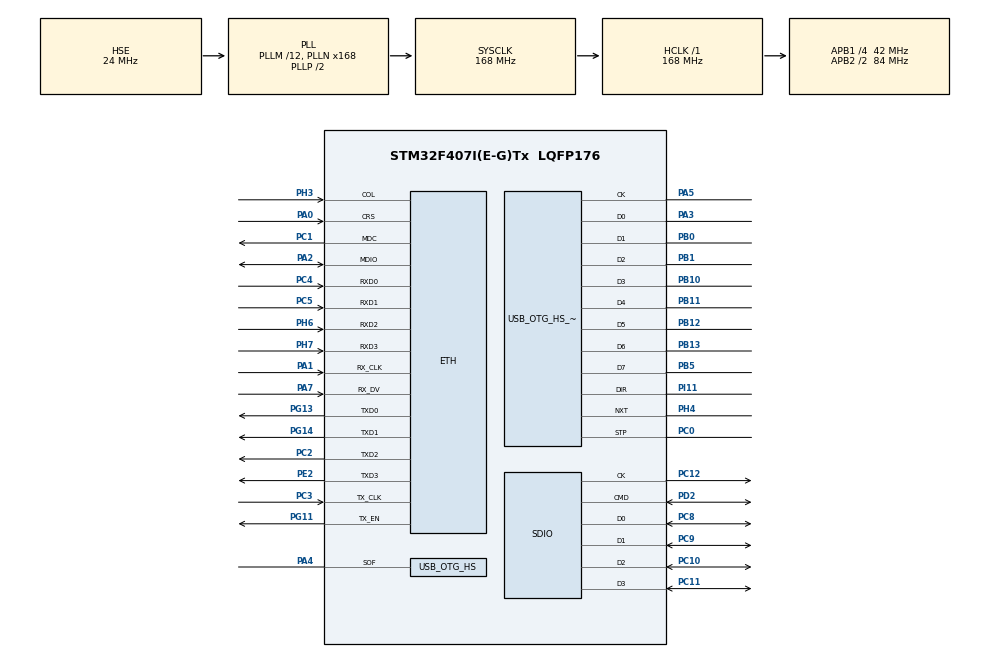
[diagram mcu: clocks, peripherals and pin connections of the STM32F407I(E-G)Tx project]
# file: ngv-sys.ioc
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LWIP.Version=v1.5.0_RC0_20160211_Cube
Mcu.Family=STM32F4
Mcu.Name=STM32F407I(E-G)Tx
Mcu.Package=LQFP176
NVIC.OTG_HS_IRQn=true\:0\:0\:false\:false\:true
NVIC.PriorityGroup=NVIC_PRIORITYGROUP_4
PA0-WKUP.Mode=MII
PA0-WKUP.Signal=ETH_CRS
PA1.Mode=MII
PA1.Signal=ETH_RX_CLK
PA2.Mode=MII
PA2.Signal=ETH_MDIO
PA3.Mode=Device_HS
PA3.Signal=USB_OTG_HS_ULPI_D0
PA4.Mode=Activate_SOF_FS
PA4.Signal=USB_OTG_HS_SOF
PA5.Mode=Device_HS
PA5.Signal=USB_OTG_HS_ULPI_CK
PA7.Mode=MII
PA7.Signal=ETH_RX_DV
PB0.Mode=Device_HS
PB0.Signal=USB_OTG_HS_ULPI_D1
PB1.Mode=Device_HS
PB1.Signal=USB_OTG_HS_ULPI_D2
PB10.Mode=Device_HS
PB10.Signal=USB_OTG_HS_ULPI_D3
PB11.Mode=Device_HS
PB11.Signal=USB_OTG_HS_ULPI_D4
PB12.Mode=Device_HS
PB12.Signal=USB_OTG_HS_ULPI_D5
PB13.Mode=Device_HS
PB13.Signal=USB_OTG_HS_ULPI_D6
PB5.Mode=Device_HS
PB5.Signal=USB_OTG_HS_ULPI_D7
PC0.Mode=Device_HS
PC0.Signal=USB_OTG_HS_ULPI_STP
PC1.Mode=MII
PC1.Signal=ETH_MDC
PC10.Mode=SD_4_bits_Wide_bus
PC10.Signal=SDIO_D2
PC11.Mode=SD_4_bits_Wide_bus
PC11.Signal=SDIO_D3
PC12.Mode=SD_4_bits_Wide_bus
PC12.Signal=SDIO_CK
PC14-OSC32_IN.Mode=LSE-External-Oscillator
PC14-OSC32_IN.Signal=RCC_OSC32_IN
PC15-OSC32_OUT.Mode=LSE-External-Oscillator
PC15-OSC32_OUT.Signal=RCC_OSC32_OUT
PC2.Mode=MII
PC2.Signal=ETH_TXD2
PC3.Mode=MII
PC3.Signal=ETH_TX_CLK
PC4.Mode=MII
PC4.Signal=ETH_RXD0
PC5.Mode=MII
PC5.Signal=ETH_RXD1
PC8.Mode=SD_4_bits_Wide_bus
PC8.Signal=SDIO_D0
PC9.Mode=SD_4_bits_Wide_bus
PC9.Signal=SDIO_D1
PD2.Mode=SD_4_bits_Wide_bus
PD2.Signal=SDIO_CMD
PE2.Mode=MII
PE2.Signal=ETH_TXD3
PG11.Mode=MII
PG11.Signal=ETH_TX_EN
PG13.Mode=MII
PG13.Signal=ETH_TXD0
PG14.Mode=MII
PG14.Signal=ETH_TXD1
PH0-OSC_IN.Mode=HSE-External-Oscillator
PH0-OSC_IN.Signal=RCC_OSC_IN
PH1-OSC_OUT.Mode=HSE-External-Oscillator
PH1-OSC_OUT.Signal=RCC_OSC_OUT
PH3.Mode=MII
PH3.Signal=ETH_COL
PH4.Mode=Device_HS
PH4.Signal=USB_OTG_HS_ULPI_NXT
PH6.Mode=MII
PH6.Signal=ETH_RXD2
PH7.Mode=MII
PH7.Signal=ETH_RXD3
PI11.Mode=Device_HS
PI11.Signal=USB_OTG_HS_ULPI_DIR
ProjectManager.HeapSize=0x200
ProjectManager.StackSize=0x400
ProjectManager.TargetToolchain=SW4STM32
RCC.48MHZClocksFreq_Value=48000000
RCC.AHBFreq_Value=168000000
RCC.APB1CLKDivider=RCC_HCLK_DIV4
RCC.APB1Freq_Value=42000000
RCC.APB1TimFreq_Value=84000000
RCC.APB2CLKDivider=RCC_HCLK_DIV2
RCC.APB2Freq_Value=84000000
RCC.APB2TimFreq_Value=168000000
RCC.CortexFreq_Value=168000000
RCC.EnbaleCSS=true
RCC.HCLKFreq_Value=168000000
RCC.HSE_VALUE=24000000
RCC.HSI_VALUE=16000000
RCC.PLLM=12
RCC.PLLN=168
RCC.PLLQ=7
RCC.PLLSourceVirtual=RCC_PLLSOURCE_HSE
RCC.SYSCLKFreq_VALUE=168000000
RCC.SYSCLKSource=RCC_SYSCLKSOURCE_PLLCLK
RCC.VCOOutputFreq_Value=336000000
SDIO.BusWide=SDIO_BUS_WIDE_1B
SDIO.WideMode=SDIO_BUS_WIDE_4B
USB_DEVICE.CLASS_NAME-MSC_HS=MSC
USB_DEVICE.USBD_HandleTypeDef-MSC_HS=hUsbDeviceHS
USB_DEVICE.VirtualMode-MSC_HS=Msc
USB_DEVICE.VirtualModeHS=Msc_HS
USB_OTG_HS.VirtualMode-Device_HS=Device_HS
VP_FATFS_VS_SDIO.Mode=SDIO
VP_LWIP_VS_Enabled.Mode=Enabled
VP_USB_DEVICE_VS_USB_DEVICE_MSC_HS.Mode=MSC_HS
board=ngv-sys

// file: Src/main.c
/**
  ******************************************************************************
  * File Name          : main.c
  * Description        : Main program body
  ******************************************************************************
  *
  * Copyright (c) 2017 STMicroelectronics International N.V.
  * All rights reserved.
  *
  * Redistribution and use in source and binary forms, with or without
  * modification, are permitted, provided that the following conditions are met:
  *
  * 1. Redistribution of source code must retain the above copyright notice,
  *    this list of conditions and the following disclaimer.
  * 2. Redistributions in binary form must reproduce the above copyright notice,
  *    this list of conditions and the following disclaimer in the documentation
  *    and/or other materials provided with the distribution.
  * 3. Neither the name of STMicroelectronics nor the names of other
  *    contributors to this software may be used to endorse or promote products
  *    derived from this software without specific written permission.
  * 4. This software, including modifications and/or derivative works of this
  *    software, must execute solely and exclusively on microcontroller or
  *    microprocessor devices manufactured by or for STMicroelectronics.
  * 5. Redistribution and use of this software other than as permitted under
  *    this license is void and will automatically terminate your rights under
  *    this license.
  *
  * THIS SOFTWARE IS PROVIDED BY STMICROELECTRONICS AND CONTRIBUTORS "AS IS"
  * AND ANY EXPRESS, IMPLIED OR STATUTORY WARRANTIES, INCLUDING, BUT NOT
  * LIMITED TO, THE IMPLIED WARRANTIES OF MERCHANTABILITY, FITNESS FOR A
  * PARTICULAR PURPOSE AND NON-INFRINGEMENT OF THIRD PARTY INTELLECTUAL PROPERTY
  * RIGHTS ARE DISCLAIMED TO THE FULLEST EXTENT PERMITTED BY LAW. IN NO EVENT
  * SHALL STMICROELECTRONICS OR CONTRIBUTORS BE LIABLE FOR ANY DIRECT, INDIRECT,
  * INCIDENTAL, SPECIAL, EXEMPLARY, OR CONSEQUENTIAL DAMAGES (INCLUDING, BUT NOT
  * LIMITED TO, PROCUREMENT OF SUBSTITUTE GOODS OR SERVICES; LOSS OF USE, DATA,
  * OR PROFITS; OR BUSINESS INTERRUPTION) HOWEVER CAUSED AND ON ANY THEORY OF
  * LIABILITY, WHETHER IN CONTRACT, STRICT LIABILITY, OR TORT (INCLUDING
  * NEGLIGENCE OR OTHERWISE) ARISING IN ANY WAY OUT OF THE USE OF THIS SOFTWARE,
  * EVEN IF ADVISED OF THE POSSIBILITY OF SUCH DAMAGE.
  *
  ******************************************************************************
  */
#include "main.h"
#include "stm32f4xx_hal.h"
#include "fatfs.h"
#include "lwip.h"
#include "usb_device.h"

/* USER CODE BEGIN Includes */
#include "usbd_core.h"
/* USER CODE END Includes */

SD_HandleTypeDef hsd;
HAL_SD_CardInfoTypedef SDCardInfo;

/* USER CODE BEGIN PV */
/* Private variables ---------------------------------------------------------*/
/* USER CODE END PV */

void SystemClock_Config(void);
void Error_Handler(void);
static void MX_GPIO_Init(void);
static void MX_SDIO_SD_Init(void);

/* USER CODE BEGIN PFP */
/* Private function prototypes -----------------------------------------------*/

/* USER CODE END PFP */

int main(void)
{

  /* MCU Configuration----------------------------------------------------------*/

  /* Reset of all peripherals, Initializes the Flash interface and the Systick. */
  HAL_Init();

  /* Configure the system clock */
  SystemClock_Config();

  /* Initialize all configured peripherals */
  MX_GPIO_Init();
  MX_SDIO_SD_Init();
  MX_FATFS_Init();
  MX_LWIP_Init();
  MX_USB_DEVICE_Init();

  /* USER CODE BEGIN 2 */
	USBD_Stop(&hUsbDeviceHS);
	HAL_SD_Init(&hsd, &SDCardInfo);
	USBD_Start(&hUsbDeviceHS);
  /* USER CODE END 2 */

  /* Infinite loop */
  while (1)
  {

  }

}

/** System Clock Configuration
*/
void SystemClock_Config(void)
{

  RCC_OscInitTypeDef RCC_OscInitStruct;
  RCC_ClkInitTypeDef RCC_ClkInitStruct;

    /**Configure the main internal regulator output voltage
    */
  __HAL_RCC_PWR_CLK_ENABLE();

  __HAL_PWR_VOLTAGESCALING_CONFIG(PWR_REGULATOR_VOLTAGE_SCALE1);

    /**Initializes the CPU, AHB and APB busses clocks
    */
  RCC_OscInitStruct.OscillatorType = RCC_OSCILLATORTYPE_HSE;
  RCC_OscInitStruct.HSEState = RCC_HSE_ON;
  RCC_OscInitStruct.PLL.PLLState = RCC_PLL_ON;
  RCC_OscInitStruct.PLL.PLLSource = RCC_PLLSOURCE_HSE;
  RCC_OscInitStruct.PLL.PLLM = 12;
  RCC_OscInitStruct.PLL.PLLN = 168;
  RCC_OscInitStruct.PLL.PLLP = RCC_PLLP_DIV2;
  RCC_OscInitStruct.PLL.PLLQ = 7;
  if (HAL_RCC_OscConfig(&RCC_OscInitStruct) != HAL_OK)
  {
    Error_Handler();
  }

    /**Initializes the CPU, AHB and APB busses clocks
    */
  RCC_ClkInitStruct.ClockType = RCC_CLOCKTYPE_HCLK|RCC_CLOCKTYPE_SYSCLK
                              |RCC_CLOCKTYPE_PCLK1|RCC_CLOCKTYPE_PCLK2;
  RCC_ClkInitStruct.SYSCLKSource = RCC_SYSCLKSOURCE_PLLCLK;
  RCC_ClkInitStruct.AHBCLKDivider = RCC_SYSCLK_DIV1;
  RCC_ClkInitStruct.APB1CLKDivider = RCC_HCLK_DIV4;
  RCC_ClkInitStruct.APB2CLKDivider = RCC_HCLK_DIV2;

  if (HAL_RCC_ClockConfig(&RCC_ClkInitStruct, FLASH_LATENCY_5) != HAL_OK)
  {
    Error_Handler();
  }

    /**Enables the Clock Security System
    */
  HAL_RCC_EnableCSS();

    /**Configure the Systick interrupt time
    */
  HAL_SYSTICK_Config(HAL_RCC_GetHCLKFreq()/1000);

    /**Configure the Systick
    */
  HAL_SYSTICK_CLKSourceConfig(SYSTICK_CLKSOURCE_HCLK);

  /* SysTick_IRQn interrupt configuration */
  HAL_NVIC_SetPriority(SysTick_IRQn, 0, 0);
}

/* SDIO init function */
static void MX_SDIO_SD_Init(void)
{

  hsd.Instance = SDIO;
  hsd.Init.ClockEdge = SDIO_CLOCK_EDGE_RISING;
  hsd.Init.ClockBypass = SDIO_CLOCK_BYPASS_DISABLE;
  hsd.Init.ClockPowerSave = SDIO_CLOCK_POWER_SAVE_DISABLE;
  hsd.Init.BusWide = SDIO_BUS_WIDE_1B;
  hsd.Init.HardwareFlowControl = SDIO_HARDWARE_FLOW_CONTROL_DISABLE;
  hsd.Init.ClockDiv = 0;

}

/** Configure pins as
        * Analog
        * Input
        * Output
        * EVENT_OUT
        * EXTI
*/
static void MX_GPIO_Init(void)
{

  /* GPIO Ports Clock Enable */
  __HAL_RCC_GPIOE_CLK_ENABLE();
  __HAL_RCC_GPIOC_CLK_ENABLE();
  __HAL_RCC_GPIOI_CLK_ENABLE();
  __HAL_RCC_GPIOH_CLK_ENABLE();
  __HAL_RCC_GPIOA_CLK_ENABLE();
  __HAL_RCC_GPIOB_CLK_ENABLE();
  __HAL_RCC_GPIOD_CLK_ENABLE();
  __HAL_RCC_GPIOG_CLK_ENABLE();

}

void Error_Handler(void)
{
  while(1)
  {
  }
}

/************************ (C) COPYRIGHT STMicroelectronics *****END OF FILE****/
